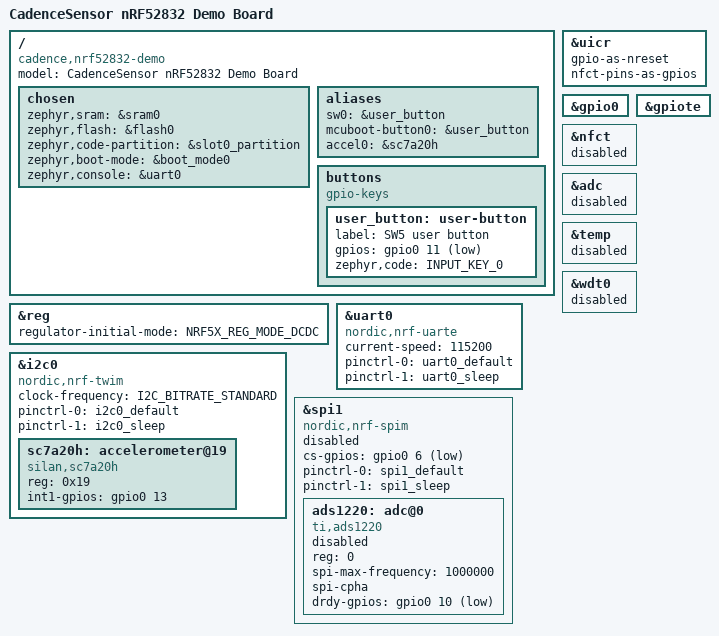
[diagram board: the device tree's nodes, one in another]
/dts-v1/;
#include <nordic/nrf52832_qfaa.dtsi>
#include <zephyr/dt-bindings/gpio/gpio.h>
#include <zephyr/dt-bindings/i2c/i2c.h>
#include <zephyr/dt-bindings/input/input-event-codes.h>
#include "cadence_sensor_nrf52832-pinctrl.dtsi"
#include "cadence_sensor_partitions.dtsi"

/ {
	model = "CadenceSensor nRF52832 Demo Board";
	compatible = "cadence,nrf52832-demo";

	chosen {
		zephyr,sram = &sram0;
		zephyr,flash = &flash0;
		zephyr,code-partition = &slot0_partition;
		zephyr,boot-mode = &boot_mode0;
		/* Physical console default; the application overlay selects NUS. */
		zephyr,console = &uart0;
	};

	aliases {
		sw0 = &user_button;
		mcuboot-button0 = &user_button;
		accel0 = &sc7a20h;
	};

	buttons {
		compatible = "gpio-keys";
		user_button: user-button {
			label = "SW5 user button";
			gpios = <&gpio0 11 (GPIO_PULL_UP | GPIO_ACTIVE_LOW)>;
			zephyr,code = <INPUT_KEY_0>;
		};
	};
};

/* X1=32 MHz is the physical HF crystal; keep the SoC's 64 MHz HFXO
 * clock output description. X2=32.768 kHz is selected in defconfig.
 * DCC -> 15 nH + 10 uH -> DEC4 and 1 uF are populated.
 */
&reg {
	regulator-initial-mode = <NRF5X_REG_MODE_DCDC>;
};

&uicr {
	gpio-as-nreset; /* SW4 / H3 RESET: P0.21. */
	nfct-pins-as-gpios; /* P0.09=MISO, P0.10=DRDY, not NFC. */
};

&gpio0 { status = "okay"; };
&gpiote { status = "okay"; };
&nfct { status = "disabled"; };
&adc { status = "disabled"; };
&temp { status = "disabled"; };
&wdt0 { status = "disabled"; };

/* Header pins P0.25/P0.26 assigned TX/RX by this project. */
&uart0 {
	compatible = "nordic,nrf-uarte";
	status = "okay";
	current-speed = <115200>;
	pinctrl-0 = <&uart0_default>;
	pinctrl-1 = <&uart0_sleep>;
	pinctrl-names = "default", "sleep";
};

&i2c0 {
	compatible = "nordic,nrf-twim";
	status = "okay";
	clock-frequency = <I2C_BITRATE_STANDARD>;
	pinctrl-0 = <&i2c0_default>;
	pinctrl-1 = <&i2c0_sleep>;
	pinctrl-names = "default", "sleep";

	sc7a20h: accelerometer@19 {
		compatible = "silan,sc7a20h";
		reg = <0x19>; /* SDO high, CS high: I2C. */
		int1-gpios = <&gpio0 13 GPIO_ACTIVE_HIGH>;
		/* ACC_INT2 is not connected to an MCU pin in this schematic. */
	};
};

/* ADS1220 wiring is recorded, but remains disabled until its firmware
 * driver is implemented. SPI0 shares the I2C0 hardware instance.
 */
&spi1 {
	compatible = "nordic,nrf-spim";
	status = "disabled";
	cs-gpios = <&gpio0 6 GPIO_ACTIVE_LOW>;
	pinctrl-0 = <&spi1_default>;
	pinctrl-1 = <&spi1_sleep>;
	pinctrl-names = "default", "sleep";

	ads1220: adc@0 {
		compatible = "ti,ads1220";
		reg = <0>;
		status = "disabled";
		/* Initial conservative limit; validate timing when enabling. */
		spi-max-frequency = <1000000>;
		spi-cpha;
		drdy-gpios = <&gpio0 10 GPIO_ACTIVE_LOW>;
	};
};
